# STM32F730x register map
File version: 1.1
CPU: CM7 r0p1, little endian, MPU, FPU, 4 interrupt priority bits
Registers are 32-bit, read-write, reset 0x0 unless marked. A register's access mark holds for its fields unless they carry their own. Offsets are from the block's base; [hi:lo] are bit positions.

## QUADSPI — QuadSPI interface
Base 0xA0001000
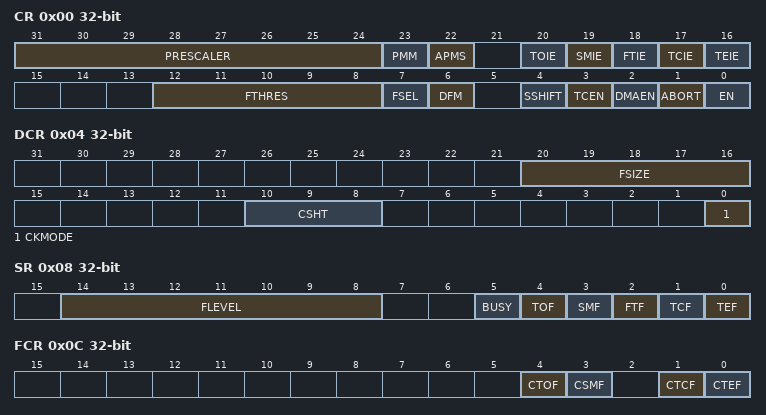
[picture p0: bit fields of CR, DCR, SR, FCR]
0x00 CR — control register
  [31:24] PRESCALER — Clock prescaler
  [23] PMM — Polling match mode
  [22] APMS — Automatic poll mode stop
  [20] TOIE — TimeOut interrupt enable
  [19] SMIE — Status match interrupt enable
  [18] FTIE — FIFO threshold interrupt enable
  [17] TCIE — Transfer complete interrupt enable
  [16] TEIE — Transfer error interrupt enable
  [12:8] FTHRES — IFO threshold level
  [7] FSEL — FLASH memory selection
  [6] DFM — Dual-flash mode
  [4] SSHIFT — Sample shift
  [3] TCEN — Timeout counter enable
  [2] DMAEN — DMA enable
  [1] ABORT — Abort request
  [0] EN — Enable
0x04 DCR — device configuration register
  [20:16] FSIZE — FLASH memory size
  [10:8] CSHT — Chip select high time
  [0] CKMODE — Mode 0 / mode 3
0x08 SR ro — status register
  [14:8] FLEVEL — FIFO level
  [5] BUSY
  [4] TOF — Timeout flag
  [3] SMF — Status match flag
  [2] FTF — FIFO threshold flag
  [1] TCF — Transfer complete flag
  [0] TEF — Transfer error flag
0x0C FCR — flag clear register
  [4] CTOF — Clear timeout flag
  [3] CSMF — Clear status match flag
  [1] CTCF — Clear transfer complete flag
  [0] CTEF — Clear transfer error flag
0x10 DLR — data length register
  [31:0] DL — Data length
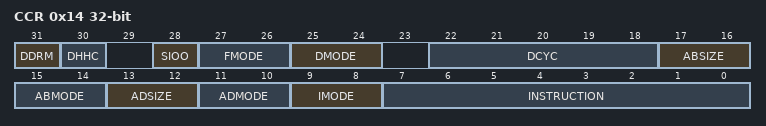
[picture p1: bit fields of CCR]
0x14 CCR — communication configuration register
  [31] DDRM — Double data rate mode
  [30] DHHC — DDR hold half cycle
  [28] SIOO — Send instruction only once mode
  [27:26] FMODE — Functional mode
  [25:24] DMODE — Data mode
  [22:18] DCYC — Number of dummy cycles
  [17:16] ABSIZE — Alternate bytes size
  [15:14] ABMODE — Alternate bytes mode
  [13:12] ADSIZE — Address size
  [11:10] ADMODE — Address mode
  [9:8] IMODE — Instruction mode
  [7:0] INSTRUCTION
0x18 AR — address register
  [31:0] ADDRESS
0x1C ABR
  [31:0] ALTERNATE
0x20 DR — data register
  [31:0] DATA
0x24 PSMKR — polling status mask register
  [31:0] MASK — Status mask
0x28 PSMAR — polling status match register
  [31:0] MATCH — Status match
0x2C PIR — polling interval register
  [15:0] INTERVAL — Polling interval
0x30 LPTR — low-power timeout register
  [15:0] TIMEOUT — Timeout period

## RNG — Random number generator
Base 0x50060800
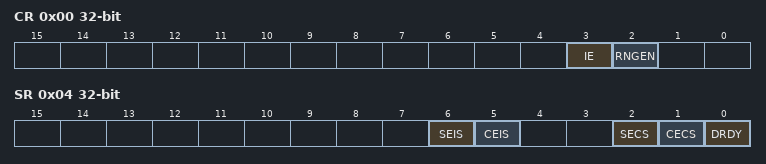
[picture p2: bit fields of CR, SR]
0x00 CR — control register
  [3] IE — Interrupt enable
  [2] RNGEN — Random number generator enable
0x04 SR access per field — status register
  [6] SEIS rw — Seed error interrupt status
  [5] CEIS rw — Clock error interrupt status
  [2] SECS ro — Seed error current status
  [1] CECS ro — Clock error current status
  [0] DRDY ro — Data ready
0x08 DR ro — data register
  [31:0] RNDATA — Random data

## SPI5 — Serial peripheral interface
Base 0x40015000
Same registers: SPI2 0x40003800, SPI3 0x40003C00, SPI1 0x40013000, SPI4 0x40013400
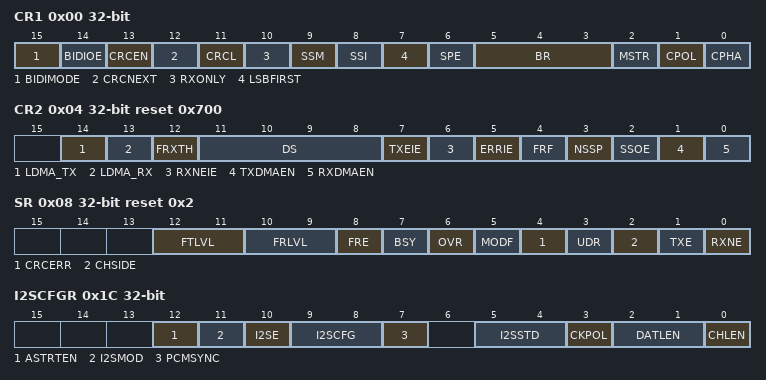
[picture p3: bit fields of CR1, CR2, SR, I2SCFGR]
0x00 CR1 — control register 1
  [15] BIDIMODE — Bidirectional data mode enable
  [14] BIDIOE — Output enable in bidirectional mode
  [13] CRCEN — Hardware CRC calculation enable
  [12] CRCNEXT — CRC transfer next
  [11] CRCL — CRC length
  [10] RXONLY — Receive only
  [9] SSM — Software slave management
  [8] SSI — Internal slave select
  [7] LSBFIRST — Frame format
  [6] SPE — SPI enable
  [5:3] BR — Baud rate control
  [2] MSTR — Master selection
  [1] CPOL — Clock polarity
  [0] CPHA — Clock phase
0x04 CR2 reset 0x700 — control register 2
  [14] LDMA_TX — Last DMA transfer for transmission
  [13] LDMA_RX — Last DMA transfer for reception
  [12] FRXTH — FIFO reception threshold
  [11:8] DS — Data size
  [7] TXEIE — Tx buffer empty interrupt enable
  [6] RXNEIE — RX buffer not empty interrupt enable
  [5] ERRIE — Error interrupt enable
  [4] FRF — Frame format
  [3] NSSP — NSS pulse management
  [2] SSOE — SS output enable
  [1] TXDMAEN — Tx buffer DMA enable
  [0] RXDMAEN — Rx buffer DMA enable
0x08 SR access per field reset 0x2 — status register
  [12:11] FTLVL ro — FIFO Transmission Level
  [10:9] FRLVL ro — FIFO reception level
  [8] FRE ro — frame format error
  [7] BSY ro — Busy flag
  [6] OVR ro — Overrun flag
  [5] MODF ro — Mode fault
  [4] CRCERR rw — CRC error flag
  [3] UDR ro — Underrun flag
  [2] CHSIDE ro — Channel side
  [1] TXE ro — Transmit buffer empty
  [0] RXNE ro — Receive buffer not empty
0x0C DR — data register
  [15:0] DR — Data register
0x10 CRCPR reset 0x7 — CRC polynomial register
  [15:0] CRCPOLY
0x14 RXCRCR ro — RX CRC register
  [15:0] RxCRC
0x18 TXCRCR ro — TX CRC register
  [15:0] TxCRC
0x1C I2SCFGR — I2S configuration register
  [12] ASTRTEN — Asynchronous start enable
  [11] I2SMOD — I2S mode selection
  [10] I2SE — I2S Enable
  [9:8] I2SCFG — I2S configuration mode
  [7] PCMSYNC — PCM frame synchronization
  [5:4] I2SSTD — I2S standard selection
  [3] CKPOL — Steady state clock polarity
  [2:1] DATLEN — Data length to be transferred
  [0] CHLEN — Channel length (number of bits per audio channel)
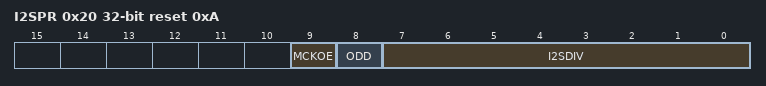
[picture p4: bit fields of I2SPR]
0x20 I2SPR reset 0xA — I2S prescaler register
  [9] MCKOE — Master clock output enable
  [8] ODD — Odd factor for the prescaler
  [7:0] I2SDIV — I2S Linear prescaler
